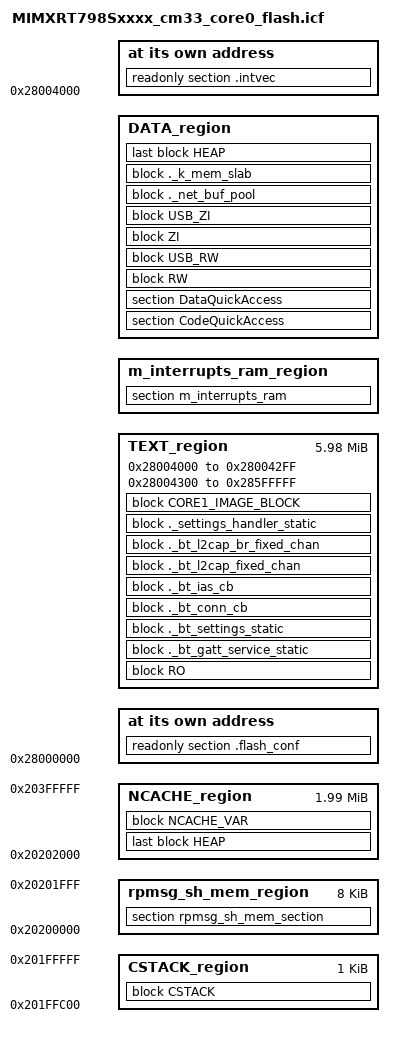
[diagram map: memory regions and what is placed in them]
/*
** ###################################################################
**     Processors:          MIMXRT798SGAWAR_cm33_core0
**                          MIMXRT798SGFOA_cm33_core0
**
**     Compiler:            IAR ANSI C/C++ Compiler for ARM
**     Reference manual:    iMXRT700RM Rev.1, 08/2022
**     Version:             rev. 1.0, 2023-11-14
**     Build:               b240227
**
**     Abstract:
**         Linker file for the IAR ANSI C/C++ Compiler for ARM
**
**     Copyright 2016 Freescale Semiconductor, Inc.
**     Copyright 2016-2024 NXP
**     SPDX-License-Identifier: BSD-3-Clause
**
**     http:                 www.nxp.com
**     mail:                 support@nxp.com
**
** ###################################################################
*/

/* Stack and Heap Sizes */
if (isdefinedsymbol(__stack_size__)) {
  define symbol __size_cstack__        = __stack_size__;
} else {
  define symbol __size_cstack__        = 0x0400;
}

if (isdefinedsymbol(__heap_size__)) {
  define symbol __size_heap__          = __heap_size__;
} else {
  define symbol __size_heap__          = 0x1000;
}

/* The SRAM region [0x000000-0x013FFF] is reserved for ROM bootloader execution. Can be reused after boot. */
/* The SRAM region [0x014000-0x07FFFF] is reserved for Non-cached shared memory or application data. */
/* The SRAM region [0x080000-0x3FFFFF] is reserved for CPU0 application, last 2MB non-cacheable data for NPU/GPU/Display etc. */
/* The SRAM region [0x400000-0x57FFFF] is reserved for HiFi4 application. */

define symbol __ram_vector_table_size__        =  isdefinedsymbol(__ram_vector_table__) ? 0x00000300 : 0;
define symbol __ram_vector_table_offset__      =  isdefinedsymbol(__ram_vector_table__) ? 0x000002FF : 0;

define symbol LITTLEFS_REGION_SIZE             = 0x00200000;

define symbol m_interrupts_start               = 0x28004000;
define symbol m_interrupts_end                 = 0x280042FF;

define symbol m_text_start                     = 0x28004300;
define symbol m_text_end                       = 0x287FFFFF - LITTLEFS_REGION_SIZE;

define symbol m_interrupts_ram_start           = 0x20080000;
define symbol m_interrupts_ram_end             = 0x20080000 + __ram_vector_table_offset__;

define symbol m_data_start                     = m_interrupts_ram_start + __ram_vector_table_size__;
define symbol m_data_end                       = 0x201FFFFF;

if (isdefinedsymbol(__use_shmem__)) {
  define exported symbol rpmsg_sh_mem_start      = 0x20200000;
  define exported symbol rpmsg_sh_mem_end        = 0x20201FFF;
  define symbol m_ncache_start                   = 0x20202000;
  define symbol m_ncache_end                     = 0x203FFFFF;
  define exported symbol __NCACHE_REGION_START   = rpmsg_sh_mem_start;
  define exported symbol __NCACHE_REGION_SIZE    = m_ncache_end - __NCACHE_REGION_START + 1;
}
else
{
  define symbol m_ncache_start                   = 0x20200000;
  define symbol m_ncache_end                     = 0x203FFFFF;
  define exported symbol __NCACHE_REGION_START   = m_ncache_start;
  define exported symbol __NCACHE_REGION_SIZE    = m_ncache_end - __NCACHE_REGION_START + 1;
}

define symbol m_core1_image_maximum_size       = 0x00080000;

define symbol m_boot_flash_conf_start          = 0x28000000;

define exported symbol __VECTOR_TABLE          = m_interrupts_start;
define exported symbol __VECTOR_RAM            = isdefinedsymbol(__ram_vector_table__) ? m_interrupts_ram_start : m_interrupts_start;
define exported symbol __RAM_VECTOR_TABLE_SIZE = __ram_vector_table_size__;

/* NOTE: The last LITTLEFS_REGION_SIZE Flash( in range (m_text_end + 1) ~ (m_text_end + LITTLEFS_REGION_SIZE)) is reserved for litteFS data */

/*** littleFS configuration Start ***/
define exported symbol EDGEFAST_BT_LITTLEFS_STORAGE_START_ADDRESS = m_text_end + 1;
define exported symbol EDGEFAST_BT_LITTLEFS_STORAGE_SECTOR_SIZE   = 0x1000;  /* 4k flash sector size */
define exported symbol EDGEFAST_BT_LITTLEFS_STORAGE_MAX_SECTORS   = LITTLEFS_REGION_SIZE / EDGEFAST_BT_LITTLEFS_STORAGE_SECTOR_SIZE;
/*** littleFS configuration End ***/

define memory mem with size = 4G;

define region TEXT_region             = mem:[from m_interrupts_start to m_interrupts_end]
                                      | mem:[from m_text_start to m_text_end];
define region m_interrupts_ram_region = mem:[from m_interrupts_ram_start to m_interrupts_ram_end];
define region DATA_region             = mem:[from m_data_start to m_data_end - __size_cstack__];
define region CSTACK_region           = mem:[from m_data_end-__size_cstack__ + 1 to m_data_end];
define region NCACHE_region           = mem:[from m_ncache_start to m_ncache_end];
if (isdefinedsymbol(__use_shmem__)) {
  define region rpmsg_sh_mem_region     = mem:[from rpmsg_sh_mem_start to rpmsg_sh_mem_end];
}

define block CSTACK    with alignment = 8, size = __size_cstack__   { };
define block HEAP      with alignment = 8, size = __size_heap__     { };
define block RO        { readonly };
define block RW        { readwrite };
define block ZI        { zi };
define block USB_RW    with alignment = 32, end alignment = 32  { section CacheLineData.init };
define block USB_ZI    with alignment = 32, end alignment = 32  { section CacheLineData };
define block NCACHE_VAR    { section NonCacheable , section NonCacheable.init };
define block CORE1_IMAGE_BLOCK  with alignment = 16, maximum size = m_core1_image_maximum_size  { section  __core1_image };

initialize by copy { readwrite, section .textrw , section CodeQuickAccess, section DataQuickAccess,
  object mflash_drv.o,
  object fsl_xspi.o,
};

do not initialize  { section .noinit };
if (isdefinedsymbol(__use_shmem__)) {
  do not initialize  { section rpmsg_sh_mem_section };
}

keep{section .flash_conf };
place at address mem: m_boot_flash_conf_start    { readonly section .flash_conf };
place at address mem: m_interrupts_start    { readonly section .intvec };

define block ._bt_gatt_service_static with fixed order { readonly section ._bt_gatt_service_static*};
define block ._bt_settings_static with fixed order { readonly section ._bt_settings*};
define block ._bt_conn_cb with fixed order { readonly section ._bt_conn_cb*};
define block ._bt_ias_cb with fixed order { readonly section ._bt_ias_cb*};
define block ._bt_l2cap_fixed_chan with fixed order { readonly section ._bt_l2cap_fixed_chan*};
define block ._bt_l2cap_br_fixed_chan with fixed order { readonly section ._bt_l2cap_br_fixed_chan*};
define block ._settings_handler_static with fixed order { readonly section ._settings_handler_static*};
define block ._k_mem_slab with fixed order { readwrite section ._k_mem_slab*};
define block ._net_buf_pool with fixed order { readwrite section ._net_buf_pool*};

place in TEXT_region                        { block RO };
place in TEXT_region                        { block ._bt_gatt_service_static, block ._bt_settings_static, block ._bt_conn_cb, block ._bt_ias_cb, block ._bt_l2cap_fixed_chan, block ._bt_l2cap_br_fixed_chan, block ._settings_handler_static };
place in TEXT_region                        { block CORE1_IMAGE_BLOCK };
place in m_interrupts_ram_region            { section m_interrupts_ram };
place in DATA_region                        { section CodeQuickAccess, section DataQuickAccess };
place in DATA_region                        { block RW, block USB_RW };
place in DATA_region                        { block ZI, block USB_ZI };
place in DATA_region                        { block ._net_buf_pool, block ._k_mem_slab };
if (isdefinedsymbol(__heap_noncacheable__)) {
  place in NCACHE_region                    { last block HEAP };
}
else {
  place in DATA_region                      { last block HEAP };
}
place in NCACHE_region                      { block NCACHE_VAR };
place in CSTACK_region                      { block CSTACK };
if (isdefinedsymbol(__use_shmem__)) {
  place in rpmsg_sh_mem_region                { section rpmsg_sh_mem_section };
}
keep { section .flash_area_list, section ._net_buf_pool*, section ._k_mem_slab*, section ._bt*, section ._settings*};
